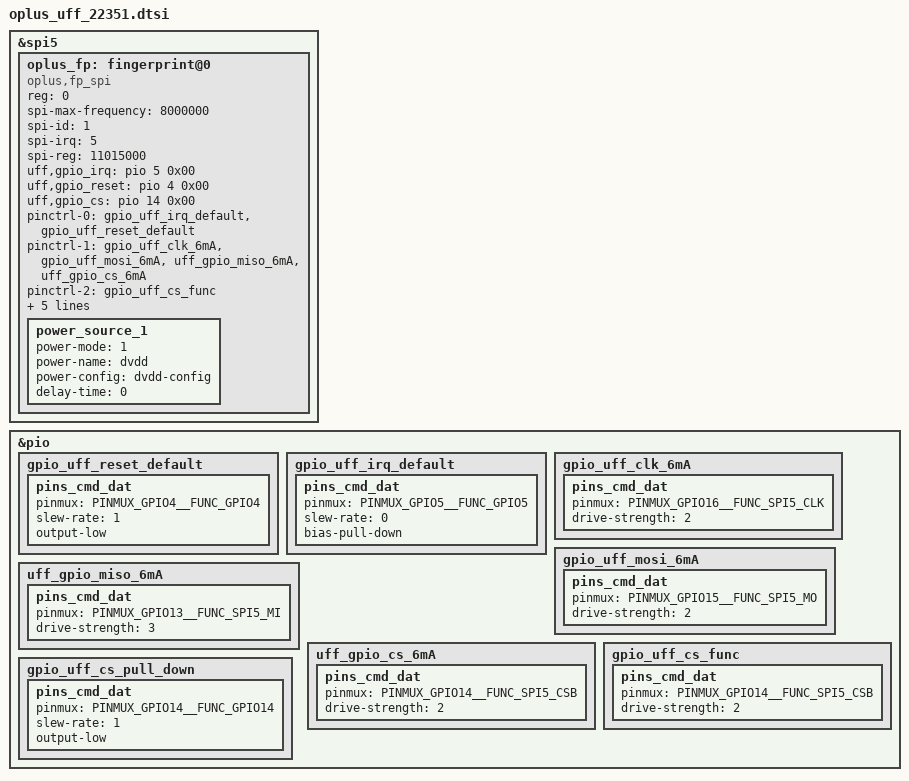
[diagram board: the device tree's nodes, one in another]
// SPDX-License-Identifier: GPL-2.0-only
/*
* Copyright (C) 2021-2025 Oplus. All rights reserved.
*/
#include <dt-bindings/iio/mt635x-auxadc.h>
#include <dt-bindings/pinctrl/mt6768-pinfunc.h>
#include <dt-bindings/pinctrl/mt65xx.h>

/* UFF dts config at 2022.06.16
 *
 * fp vendor:
 *   jiiov: 0301
 *   jiiov: 0101
 */

&spi5 {
#address-cells = <1>;
#size-cells = <0>;
status = "okay";

oplus_fp: fingerprint@0 {
    /* UFF especial */
    compatible = "oplus,fp_spi";

    reg = <0>;
    spi-max-frequency = <8000000>;
    spi-id = <1>;
    spi-irq = <5>;
    spi-reg = <11015000>;

    /* UFF gpio begin */
    /* UFF gpio irq */
    uff,gpio_irq = <&pio 5 0x00>;

    /* UFF gpio rst */
    uff,gpio_reset = <&pio 4 0x00>;

    /* UFF gpio cs */
    uff,gpio_cs = <&pio 14 0x00>;

    pinctrl-names = "default", "fp_spi_driver", "fp_cs_func", "gpio_cs_pull_down";
    pinctrl-0 = <&gpio_uff_irq_default>, <&gpio_uff_reset_default>;
    pinctrl-1 = <&gpio_uff_clk_6mA>, <&gpio_uff_mosi_6mA>, <&uff_gpio_miso_6mA>, <&uff_gpio_cs_6mA>;
    pinctrl-2 = <&gpio_uff_cs_func>;
    pinctrl-3 = <&gpio_uff_cs_pull_down>;
    notify_tpinfo_flag = <1>;
    status = "okay";

    dvdd-supply = <&mt_pmic_vcama2_ldo_reg>;
    dvdd-config = <3000000 3000000 150000>;
    power-num = <1>;
    power_source_1 {
        power-mode = <1>;
        power-name = "dvdd";
        power-config = "dvdd-config";
        delay-time = <0>;
    };
};
};

&pio{
    gpio_uff_reset_default: gpio_uff_reset_default {
        pins_cmd_dat {
            pinmux = <PINMUX_GPIO4__FUNC_GPIO4>;
            slew-rate = <1>;
            output-low;
        };
    };

    gpio_uff_irq_default: gpio_uff_irq_default {
        pins_cmd_dat {
            pinmux = <PINMUX_GPIO5__FUNC_GPIO5>;
            slew-rate = <0>;
            bias-pull-down;
        };
    };

    gpio_uff_clk_6mA: gpio_uff_clk_6mA {
        pins_cmd_dat {
            pinmux = <PINMUX_GPIO16__FUNC_SPI5_CLK>;
            drive-strength = <2>;
        };
    };

    gpio_uff_mosi_6mA: gpio_uff_mosi_6mA {
        pins_cmd_dat {
            pinmux = <PINMUX_GPIO15__FUNC_SPI5_MO>;
            drive-strength = <2>;
        };
    };

    uff_gpio_miso_6mA: uff_gpio_miso_6mA {
        pins_cmd_dat {
            pinmux = <PINMUX_GPIO13__FUNC_SPI5_MI>;
            drive-strength = <3>;
        };
    };

    uff_gpio_cs_6mA: uff_gpio_cs_6mA{
        pins_cmd_dat {
            pinmux = <PINMUX_GPIO14__FUNC_SPI5_CSB>;
            drive-strength = <2>;
        };
    };

    gpio_uff_cs_func: gpio_uff_cs_func {
        pins_cmd_dat {
            pinmux = <PINMUX_GPIO14__FUNC_SPI5_CSB>;
            drive-strength = <2>;
        };
    };

    gpio_uff_cs_pull_down:gpio_uff_cs_pull_down{
        pins_cmd_dat{
            pinmux = <PINMUX_GPIO14__FUNC_GPIO14>;
            slew-rate = <1>;
            output-low;
        };
    };
};
